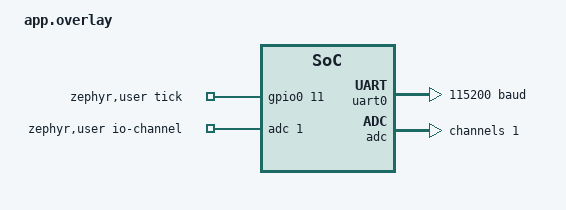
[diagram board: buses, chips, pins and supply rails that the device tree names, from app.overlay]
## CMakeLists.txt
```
# SPDX-License-Identifier: Apache-2.0

cmake_minimum_required(VERSION 3.20.0)
find_package(Zephyr REQUIRED HINTS $ENV{ZEPHYR_BASE})
project(nohrd_bike)

target_sources(app PRIVATE src/main.c src/ble_ftms.c src/ble_hr.c)
```

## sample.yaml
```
sample:
  name: NOHRD Bike Controller
tests:
  app.nohrd_bike:
    tags:
      - bike
      - display
      - bluetooth
      - gpio
    depends_on:
      - gpio
      - adc
      - bluetooth
    harness: led
    integration_platforms:
      - nrf52dk_nrf52832
```

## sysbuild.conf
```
SB_CONFIG_BOOTLOADER_MCUBOOT=y
SB_CONFIG_BOOT_SIGNATURE_TYPE_ECDSA_P256=y
SB_CONFIG_BOOT_SIGNATURE_KEY_FILE="${APPLICATION_CONFIG_DIR}/keys/nohrd-bike-mcuboot-ec256.pem"
SB_CONFIG_PM_EXTERNAL_FLASH_MCUBOOT_SECONDARY=y
```

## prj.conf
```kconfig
CONFIG_GPIO=y
CONFIG_ADC=y
CONFIG_FLASH=y
CONFIG_FLASH_MAP=y
CONFIG_FLASH_PAGE_LAYOUT=y
CONFIG_NVS=y
CONFIG_SPI=y
CONFIG_SPI_NOR=y
CONFIG_SPI_NOR_SFDP_MINIMAL=y
CONFIG_SPI_NOR_FLASH_LAYOUT_PAGE_SIZE=4096
CONFIG_SERIAL=y
CONFIG_UART_INTERRUPT_DRIVEN=y
CONFIG_CONSOLE=n
CONFIG_UART_CONSOLE=n
CONFIG_BT=y
CONFIG_BT_PERIPHERAL=y
CONFIG_BT_CENTRAL=y
CONFIG_BT_GATT_CLIENT=y
CONFIG_BT_GATT_DYNAMIC_DB=y
CONFIG_BT_MAX_CONN=2
CONFIG_BT_DEVICE_NAME="NOHRDNB"
CONFIG_BT_DEVICE_APPEARANCE=1152
CONFIG_BT_DIS=y
CONFIG_BT_DIS_MANUF_NAME=y
CONFIG_BT_DIS_MANUF_NAME_STR="waterrower nohrd"
CONFIG_BT_DIS_HW_REV=y
CONFIG_BT_DIS_HW_REV_STR="4.0"
CONFIG_BT_DIS_FW_REV=y
CONFIG_BT_DIS_FW_REV_STR="4.0"
CONFIG_BT_DIS_SW_REV=y
CONFIG_BT_DIS_SW_REV_STR="4.9"
```

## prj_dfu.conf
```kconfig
CONFIG_STREAM_FLASH=y
CONFIG_IMG_MANAGER=y
CONFIG_IMG_ERASE_PROGRESSIVELY=y
CONFIG_BOOTLOADER_MCUBOOT=y
CONFIG_MCUBOOT_BOOTUTIL_LIB=y
CONFIG_SPI=y
CONFIG_SPI_NOR=y
CONFIG_SPI_NOR_SFDP_MINIMAL=y
CONFIG_SPI_NOR_FLASH_LAYOUT_PAGE_SIZE=4096

CONFIG_NET_BUF=y
CONFIG_ZCBOR=y
CONFIG_CRC=y
CONFIG_MCUMGR=y
CONFIG_MCUMGR_GRP_IMG=y
CONFIG_MCUMGR_GRP_OS=y
CONFIG_MCUMGR_TRANSPORT_BT=y
CONFIG_MCUMGR_TRANSPORT_BT_PERM_RW=y
CONFIG_MCUMGR_TRANSPORT_BT_CONN_PARAM_CONTROL=y
CONFIG_MCUMGR_TRANSPORT_BT_REASSEMBLY=y
CONFIG_MCUMGR_TRANSPORT_NETBUF_SIZE=1220
CONFIG_MCUMGR_GRP_OS_MCUMGR_PARAMS=y
CONFIG_MCUMGR_TRANSPORT_WORKQUEUE_STACK_SIZE=4608
CONFIG_MCUMGR_TRANSPORT_UART=n

CONFIG_BT_L2CAP_TX_MTU=247
CONFIG_BT_BUF_ACL_RX_SIZE=251
CONFIG_BT_BUF_ACL_TX_SIZE=251
CONFIG_BT_CTLR_DATA_LENGTH_MAX=251
CONFIG_BT_ASSERT=n
CONFIG_BT_DIS_MODEL_NUMBER=n
CONFIG_BT_DIS_PNP=n
CONFIG_SYSTEM_WORKQUEUE_STACK_SIZE=2304
CONFIG_MAIN_STACK_SIZE=3072

CONFIG_MINIMAL_LIBC=y
```

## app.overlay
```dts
&pinctrl {
	uart0_default: uart0_default {
		group1 {
			psels = <NRF_PSEL(UART_TX, 0, 6)>,
				<NRF_PSEL(UART_RX, 0, 8)>;
		};
	};

	uart0_sleep: uart0_sleep {
		group1 {
			psels = <NRF_PSEL(UART_RX, 0, 8)>;
			low-power-enable;
		};

		group2 {
			psels = <NRF_PSEL(UART_TX, 0, 6)>;
			low-power-enable;
			bias-pull-up;
		};
	};
};

&uart0 {
	status = "okay";
	current-speed = <115200>;
	/delete-property/ hw-flow-control;
};

/ {
	zephyr,user {
		io-channels = <&adc 1>;
		tick-gpios = <&gpio0 11 GPIO_ACTIVE_HIGH>;
	};
};

&adc {
	#address-cells = <1>;
	#size-cells = <0>;
	status = "okay";

	channel@1 {
		reg = <1>;
		zephyr,gain = "ADC_GAIN_1_6";
		zephyr,reference = "ADC_REF_INTERNAL";
		zephyr,acquisition-time = <ADC_ACQ_TIME_DEFAULT>;
		zephyr,input-positive = <NRF_SAADC_AIN1>;
		zephyr,resolution = <12>;
	};
};
```

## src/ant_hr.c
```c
#include "ant_hr.h"

#include <errno.h>

static enum ant_hr_state ant_state = ANT_HR_UNAVAILABLE;

int ant_hr_init(void)
{
	return -ENOTSUP;
}

int ant_hr_start_pairing(void)
{
	ant_state = ANT_HR_UNAVAILABLE;
	return -ENOTSUP;
}

int ant_hr_disconnect(void)
{
	ant_state = ANT_HR_UNAVAILABLE;
	return 0;
}

void ant_hr_process(void)
{
}

enum ant_hr_state ant_hr_get_state(void)
{
	return ant_state;
}

bool ant_hr_is_connected(void)
{
	return ant_state == ANT_HR_CONNECTED;
}

uint8_t ant_hr_get_bpm(void)
{
	return 0U;
}

const char *ant_hr_get_name(void)
{
	return "ANT+";
}
```

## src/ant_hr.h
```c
#ifndef ANT_HR_H
#define ANT_HR_H

#include <stdbool.h>
#include <stdint.h>

enum ant_hr_state {
	ANT_HR_IDLE,
	ANT_HR_SEARCHING,
	ANT_HR_CONNECTED,
	ANT_HR_FAILED,
	ANT_HR_UNAVAILABLE,
};

int ant_hr_init(void);
int ant_hr_start_pairing(void);
int ant_hr_disconnect(void);
void ant_hr_process(void);
enum ant_hr_state ant_hr_get_state(void);
bool ant_hr_is_connected(void);
uint8_t ant_hr_get_bpm(void);
const char *ant_hr_get_name(void);

#endif
```

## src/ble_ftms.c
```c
#include "ble_ftms.h"

#include <errno.h>
#include <stddef.h>
#include <string.h>
#include <zephyr/bluetooth/bluetooth.h>
#include <zephyr/bluetooth/conn.h>
#include <zephyr/bluetooth/gatt.h>
#include <zephyr/bluetooth/uuid.h>
#ifdef CONFIG_MCUMGR_TRANSPORT_BT
#include <zephyr/mgmt/mcumgr/transport/smp_bt.h>
#endif
#include <zephyr/sys/byteorder.h>

#define BT_UUID_FTMS_VAL 0x1826
#define BT_UUID_FTMS_FEATURE_VAL 0x2acc
#define BT_UUID_INDOOR_BIKE_DATA_VAL 0x2ad2
#define BT_UUID_SUPPORTED_INCLINATION_RANGE_VAL 0x2ad5
#define BT_UUID_SUPPORTED_RESISTANCE_RANGE_VAL 0x2ad6
#define BT_UUID_SUPPORTED_HEART_RATE_RANGE_VAL 0x2ad7
#define BT_UUID_SUPPORTED_POWER_RANGE_VAL 0x2ad8
#define BT_UUID_FITNESS_MACHINE_STATUS_VAL 0x2ada

#define FTMS_STATUS_STOPPED_OR_PAUSED_BY_USER 0x02
#define FTMS_STATUS_STARTED_OR_RESUMED_BY_USER 0x04

static struct bt_conn *current_conn;
static bool bt_ready;
static bool ftms_enabled;
static bool ftms_advertising;
static bool heart_rate_notify_enabled;
static bool indoor_bike_notify_enabled;
static bool ftms_status_notify_enabled;
static bool custom_nohrd_indicate_enabled;
static bool custom_nohrd_notify_enabled;
static int ftms_last_error;
static bool custom_nohrd_indication_pending;
static const uint8_t *custom_nohrd_queued_data;
static size_t custom_nohrd_queued_len;
static struct bt_gatt_indicate_params custom_nohrd_indicate_params;
static ble_ftms_calibration_status_cb_t calibration_status_cb;
static ble_ftms_calibration_set_cb_t calibration_set_cb;

static const struct bt_uuid_16 heart_rate_service_uuid = BT_UUID_INIT_16(BT_UUID_HRS_VAL);
static const struct bt_uuid_16 heart_rate_measurement_uuid =
	BT_UUID_INIT_16(BT_UUID_HRS_MEASUREMENT_VAL);
static const struct bt_uuid_16 ftms_uuid = BT_UUID_INIT_16(BT_UUID_FTMS_VAL);
static const struct bt_uuid_16 ftms_feature_uuid =
	BT_UUID_INIT_16(BT_UUID_FTMS_FEATURE_VAL);
static const struct bt_uuid_16 supported_inclination_range_uuid =
	BT_UUID_INIT_16(BT_UUID_SUPPORTED_INCLINATION_RANGE_VAL);
static const struct bt_uuid_16 supported_resistance_range_uuid =
	BT_UUID_INIT_16(BT_UUID_SUPPORTED_RESISTANCE_RANGE_VAL);
static const struct bt_uuid_16 supported_heart_rate_range_uuid =
	BT_UUID_INIT_16(BT_UUID_SUPPORTED_HEART_RATE_RANGE_VAL);
static const struct bt_uuid_16 supported_power_range_uuid =
	BT_UUID_INIT_16(BT_UUID_SUPPORTED_POWER_RANGE_VAL);
static const struct bt_uuid_16 indoor_bike_data_uuid =
	BT_UUID_INIT_16(BT_UUID_INDOOR_BIKE_DATA_VAL);
static const struct bt_uuid_16 fitness_machine_status_uuid =
	BT_UUID_INIT_16(BT_UUID_FITNESS_MACHINE_STATUS_VAL);
static const struct bt_uuid_128 custom_nohrd_bike_service_uuid =
	BT_UUID_INIT_128(BT_UUID_128_ENCODE(0x00001001, 0xc042, 0x66ba,
					    0x1335, 0x90118f542c77));
static const struct bt_uuid_128 custom_nohrd_bike_write_uuid =
	BT_UUID_INIT_128(BT_UUID_128_ENCODE(0x8ec92001, 0xf315, 0x4f60,
					    0x9fb8, 0x838830daea50));
static const struct bt_uuid_128 custom_nohrd_bike_notify_uuid =
	BT_UUID_INIT_128(BT_UUID_128_ENCODE(0x8ec92002, 0xf315, 0x4f60,
					    0x9fb8, 0x838830daea50));

extern const struct bt_gatt_service_static ftms_service;
extern const struct bt_gatt_service_static custom_nohrd_bike_service;

static const uint8_t ftms_feature[8] = {
	0x04, 0x04, 0x00, 0x00,
	0x00, 0x00, 0x00, 0x00,
};
static const uint8_t supported_inclination_range[6] = {
	0x18, 0xfc, 0xe8, 0x03, 0x01, 0x00,
};
static const uint8_t supported_resistance_range[6] = {
	0x00, 0x00, 0xe8, 0x03, 0x01, 0x00,
};
static const uint8_t supported_heart_rate_range[3] = {
	0x00, 0xff, 0x01,
};
static const uint8_t supported_power_range[6] = {
	0x00, 0x00, 0xa0, 0x0f, 0x01, 0x00,
};

static const struct bt_data advertising_data[] = {
	BT_DATA_BYTES(BT_DATA_FLAGS, (BT_LE_AD_GENERAL | BT_LE_AD_NO_BREDR)),
	BT_DATA_BYTES(BT_DATA_UUID16_ALL,
		      BT_UUID_16_ENCODE(BT_UUID_FTMS_VAL),
		      BT_UUID_16_ENCODE(BT_UUID_DIS_VAL)),
	BT_DATA_BYTES(BT_DATA_SVC_DATA16, BT_UUID_16_ENCODE(BT_UUID_FTMS_VAL),
		      0x01, 0x20, 0x00),
	BT_DATA(BT_DATA_NAME_COMPLETE, CONFIG_BT_DEVICE_NAME,
		sizeof(CONFIG_BT_DEVICE_NAME) - 1),
};

#ifdef CONFIG_MCUMGR_TRANSPORT_BT
static const struct bt_data scan_response_data[] = {
	BT_DATA_BYTES(BT_DATA_UUID128_ALL, SMP_BT_SVC_UUID_VAL),
};
#endif

static ssize_t read_ftms_feature(struct bt_conn *conn,
				 const struct bt_gatt_attr *attr,
				 void *buf, uint16_t len, uint16_t offset)
{
	return bt_gatt_attr_read(conn, attr, buf, len, offset,
				 ftms_feature, sizeof(ftms_feature));
}

static ssize_t read_supported_inclination_range(struct bt_conn *conn,
						const struct bt_gatt_attr *attr,
						void *buf, uint16_t len,
						uint16_t offset)
{
	return bt_gatt_attr_read(conn, attr, buf, len, offset,
				 supported_inclination_range,
				 sizeof(supported_inclination_range));
}

static ssize_t read_supported_resistance_range(struct bt_conn *conn,
					       const struct bt_gatt_attr *attr,
					       void *buf, uint16_t len,
					       uint16_t offset)
{
	return bt_gatt_attr_read(conn, attr, buf, len, offset,
				 supported_resistance_range,
				 sizeof(supported_resistance_range));
}

static ssize_t read_supported_heart_rate_range(struct bt_conn *conn,
					       const struct bt_gatt_attr *attr,
					       void *buf, uint16_t len,
					       uint16_t offset)
{
	return bt_gatt_attr_read(conn, attr, buf, len, offset,
				 supported_heart_rate_range,
				 sizeof(supported_heart_rate_range));
}

static ssize_t read_supported_power_range(struct bt_conn *conn,
					  const struct bt_gatt_attr *attr,
					  void *buf, uint16_t len,
					  uint16_t offset)
{
	return bt_gatt_attr_read(conn, attr, buf, len, offset,
				 supported_power_range,
				 sizeof(supported_power_range));
}

static void heart_rate_ccc_changed(const struct bt_gatt_attr *attr,
				   uint16_t value)
{
	ARG_UNUSED(attr);

	heart_rate_notify_enabled = (value == BT_GATT_CCC_NOTIFY);
}

static void indoor_bike_ccc_changed(const struct bt_gatt_attr *attr,
				    uint16_t value)
{
	ARG_UNUSED(attr);

	indoor_bike_notify_enabled = (value == BT_GATT_CCC_NOTIFY);
}

static void fitness_machine_status_ccc_changed(const struct bt_gatt_attr *attr,
					       uint16_t value)
{
	ARG_UNUSED(attr);

	ftms_status_notify_enabled = (value == BT_GATT_CCC_NOTIFY);
}

static void custom_nohrd_ccc_changed(const struct bt_gatt_attr *attr,
				     uint16_t value)
{
	ARG_UNUSED(attr);

	custom_nohrd_indicate_enabled = (value == BT_GATT_CCC_INDICATE);
}

static void custom_nohrd_notify_ccc_changed(const struct bt_gatt_attr *attr,
					    uint16_t value)
{
	ARG_UNUSED(attr);

	custom_nohrd_notify_enabled = (value == BT_GATT_CCC_NOTIFY);
}

static int custom_nohrd_start_indication(const uint8_t *data, size_t len);

static void custom_nohrd_indicate_cb(struct bt_conn *conn,
				     struct bt_gatt_indicate_params *params,
				     uint8_t err)
{
	const uint8_t *queued_data;
	size_t queued_len;

	ARG_UNUSED(conn);
	ARG_UNUSED(params);
	ARG_UNUSED(err);

	custom_nohrd_indication_pending = false;

	if (custom_nohrd_queued_data != NULL) {
		queued_data = custom_nohrd_queued_data;
		queued_len = custom_nohrd_queued_len;
		custom_nohrd_queued_data = NULL;
		custom_nohrd_queued_len = 0U;
		(void)custom_nohrd_start_indication(queued_data, queued_len);
	}
}

static int custom_nohrd_start_indication(const uint8_t *data, size_t len)
{
	int err;

	if (current_conn == NULL || !custom_nohrd_indicate_enabled) {
		return 0;
	}

	memset(&custom_nohrd_indicate_params, 0,
	       sizeof(custom_nohrd_indicate_params));
	custom_nohrd_indicate_params.attr = &custom_nohrd_bike_service.attrs[2];
	custom_nohrd_indicate_params.data = data;
	custom_nohrd_indicate_params.len = len;
	custom_nohrd_indicate_params.func = custom_nohrd_indicate_cb;
	custom_nohrd_indication_pending = true;

	err = bt_gatt_indicate(current_conn, &custom_nohrd_indicate_params);
	if (err != 0) {
		custom_nohrd_indication_pending = false;
	}

	return err;
}

static int custom_nohrd_send(const uint8_t *data, size_t len)
{
	if (current_conn == NULL) {
		return 0;
	}

	if (custom_nohrd_notify_enabled) {
		return bt_gatt_notify_uuid(current_conn,
					   &custom_nohrd_bike_notify_uuid.uuid,
					   custom_nohrd_bike_service.attrs,
					   data, len);
	}

	if (!custom_nohrd_indicate_enabled || custom_nohrd_indication_pending) {
		if (custom_nohrd_indicate_enabled &&
		    custom_nohrd_queued_data == NULL) {
			custom_nohrd_queued_data = data;
			custom_nohrd_queued_len = len;
		}
		return 0;
	}

	return custom_nohrd_start_indication(data, len);
}

static void custom_nohrd_send_response(bool success)
{
	static const uint8_t response_success[] = {
		0xe2, 0xb0, 0xfe, 0x01, 0x01, 0x01, 0x00, 0x00,
	};
	static const uint8_t response_fail[] = {
		0xe2, 0xb0, 0xfe, 0x01, 0x02, 0x01, 0x00, 0x00,
	};

	(void)custom_nohrd_send(success ? response_success : response_fail,
				success ? sizeof(response_success) :
					  sizeof(response_fail));
}

static void custom_nohrd_send_calibrated(bool calibrated)
{
	static const uint8_t calibrated_ack[] = {
		0xe2, 0xb0, 0xfe, 0x40, 0x01, 0x00, 0x00, 0x00,
	};
	static const uint8_t calibrated_nack[] = {
		0xe2, 0xb0, 0xfe, 0x40, 0x02, 0x00, 0x00, 0x00,
	};

	(void)custom_nohrd_send(calibrated ? calibrated_ack : calibrated_nack,
				calibrated ? sizeof(calibrated_ack) :
					     sizeof(calibrated_nack));
}

static void custom_nohrd_send_transition(uint8_t transition)
{
	static const uint8_t ready[] = {0xe2, 0xd2, 0x00};
	static const uint8_t in_use[] = {0xe2, 0xd2, 0x01};
	static const uint8_t finished[] = {0xe2, 0xd2, 0x02};
	const uint8_t *data = ready;

	if (transition == 0x01) {
		data = in_use;
	} else if (transition == 0x02) {
		data = finished;
	}

	(void)custom_nohrd_send(data, sizeof(ready));
}

static int ftms_notify_status(uint8_t status, uint8_t parameter)
{
	uint8_t data[] = {status, parameter};

	if (current_conn == NULL || !ftms_status_notify_enabled) {
		return 0;
	}

	return bt_gatt_notify_uuid(current_conn,
				   &fitness_machine_status_uuid.uuid,
				   ftms_service.attrs, data, sizeof(data));
}

static int custom_nohrd_protocol_offset(const uint8_t *data, size_t len)
{
	for (size_t i = 0; i < len; i++) {
		if (data[i] == 0xfe) {
			return (int)i;
		}
	}

	return -1;
}

static ssize_t write_custom_nohrd(struct bt_conn *conn,
				  const struct bt_gatt_attr *attr,
				  const void *buf, uint16_t len,
				  uint16_t offset, uint8_t flags)
{
	const uint8_t *data = buf;
	bool success = false;
	int protocol_offset;
	size_t cmd_offset;

	ARG_UNUSED(conn);
	ARG_UNUSED(attr);
	ARG_UNUSED(flags);

	if (offset != 0U) {
		return BT_GATT_ERR(BT_ATT_ERR_INVALID_OFFSET);
	}

	protocol_offset = custom_nohrd_protocol_offset(data, len);
	if (protocol_offset < 0 || (size_t)protocol_offset + 2U >= len) {
		custom_nohrd_send_response(false);
		return len;
	}

	cmd_offset = (size_t)protocol_offset + 1U;

	switch (data[cmd_offset]) {
	case 0x01:
		if (cmd_offset + 1U < len && calibration_set_cb != NULL) {
			success = calibration_set_cb(data[cmd_offset + 1U],
						    &data[cmd_offset + 2U],
						    len - (cmd_offset + 2U)) == 0;
		}
		custom_nohrd_send_response(success);
		break;
	case 0x02:
		success = cmd_offset + 1U < len &&
			  (data[cmd_offset + 1U] == 0x01 ||
			   data[cmd_offset + 1U] == 0x02);
		custom_nohrd_send_response(success);
		break;
	case 0x04:
		custom_nohrd_send_response(true);
		custom_nohrd_send_calibrated(calibration_status_cb != NULL &&
					     calibration_status_cb());
		break;
	default:
		custom_nohrd_send_response(false);
		break;
	}

	return len;
}

/* Registered dynamically (see ble_ftms_hrs_set_active) only once a BLE HR
 * sensor is actually connected, so idle FTMS-only clients never see an
 * advertised Heart Rate Service that has no data behind it. */
static const struct bt_gatt_attr heart_rate_attrs[] = {
	BT_GATT_PRIMARY_SERVICE(&heart_rate_service_uuid.uuid),
	BT_GATT_CHARACTERISTIC(&heart_rate_measurement_uuid.uuid,
			       BT_GATT_CHRC_NOTIFY,
			       BT_GATT_PERM_NONE,
			       NULL, NULL, NULL),
	BT_GATT_CCC(heart_rate_ccc_changed,
		    BT_GATT_PERM_READ | BT_GATT_PERM_WRITE),
};

static struct bt_gatt_service heart_rate_service = BT_GATT_SERVICE(heart_rate_attrs);
static bool heart_rate_service_registered;

BT_GATT_SERVICE_DEFINE(ftms_service,
	BT_GATT_PRIMARY_SERVICE(&ftms_uuid.uuid),
	BT_GATT_CHARACTERISTIC(&ftms_feature_uuid.uuid,
			       BT_GATT_CHRC_READ,
			       BT_GATT_PERM_READ,
			       read_ftms_feature, NULL, NULL),
	BT_GATT_CHARACTERISTIC(&supported_inclination_range_uuid.uuid,
			       BT_GATT_CHRC_READ,
			       BT_GATT_PERM_READ,
			       read_supported_inclination_range, NULL, NULL),
	BT_GATT_CHARACTERISTIC(&supported_resistance_range_uuid.uuid,
			       BT_GATT_CHRC_READ,
			       BT_GATT_PERM_READ,
			       read_supported_resistance_range, NULL, NULL),
	BT_GATT_CHARACTERISTIC(&supported_heart_rate_range_uuid.uuid,
			       BT_GATT_CHRC_READ,
			       BT_GATT_PERM_READ,
			       read_supported_heart_rate_range, NULL, NULL),
	BT_GATT_CHARACTERISTIC(&supported_power_range_uuid.uuid,
			       BT_GATT_CHRC_READ,
			       BT_GATT_PERM_READ,
			       read_supported_power_range, NULL, NULL),
	BT_GATT_CHARACTERISTIC(&indoor_bike_data_uuid.uuid,
			       BT_GATT_CHRC_NOTIFY,
			       BT_GATT_PERM_NONE,
			       NULL, NULL, NULL),
	BT_GATT_CCC(indoor_bike_ccc_changed,
		    BT_GATT_PERM_READ | BT_GATT_PERM_WRITE),
	BT_GATT_CHARACTERISTIC(&fitness_machine_status_uuid.uuid,
			       BT_GATT_CHRC_NOTIFY,
			       BT_GATT_PERM_NONE,
			       NULL, NULL, NULL),
	BT_GATT_CCC(fitness_machine_status_ccc_changed,
		    BT_GATT_PERM_READ | BT_GATT_PERM_WRITE),
);

BT_GATT_SERVICE_DEFINE(custom_nohrd_bike_service,
	BT_GATT_PRIMARY_SERVICE(&custom_nohrd_bike_service_uuid.uuid),
	BT_GATT_CHARACTERISTIC(&custom_nohrd_bike_write_uuid.uuid,
			       BT_GATT_CHRC_WRITE |
			       BT_GATT_CHRC_INDICATE,
			       BT_GATT_PERM_WRITE,
			       NULL, write_custom_nohrd, NULL),
	BT_GATT_CCC(custom_nohrd_ccc_changed,
		    BT_GATT_PERM_READ | BT_GATT_PERM_WRITE),
	BT_GATT_CHARACTERISTIC(&custom_nohrd_bike_notify_uuid.uuid,
			       BT_GATT_CHRC_NOTIFY,
			       BT_GATT_PERM_NONE,
			       NULL, NULL, NULL),
	BT_GATT_CCC(custom_nohrd_notify_ccc_changed,
		    BT_GATT_PERM_READ | BT_GATT_PERM_WRITE),
);

static int start_advertising(void)
{
	int err;

	if (!bt_ready || ftms_advertising || current_conn != NULL) {
		return 0;
	}

	err = bt_le_adv_start(BT_LE_ADV_CONN_FAST_2,
			      advertising_data, ARRAY_SIZE(advertising_data),
#ifdef CONFIG_MCUMGR_TRANSPORT_BT
			      scan_response_data, ARRAY_SIZE(scan_response_data));
#else
			      NULL, 0);
#endif
	if (err == -EALREADY) {
		err = 0;
	}

	if (err == 0) {
		ftms_advertising = true;
	}

	return err;
}

static int stop_advertising(void)
{
	int err;

	if (!ftms_advertising) {
		return 0;
	}

	err = bt_le_adv_stop();
	if (err == -EALREADY || err == -EINVAL || err == -EACCES) {
		err = 0;
	}

	if (err == 0) {
		ftms_advertising = false;
	}

	return err;
}

int ble_ftms_hrs_set_active(bool active)
{
	int err;

	if (active == heart_rate_service_registered) {
		return 0;
	}

	if (active) {
		err = bt_gatt_service_register(&heart_rate_service);
	} else {
		heart_rate_notify_enabled = false;
		err = bt_gatt_service_unregister(&heart_rate_service);
	}

	if (err == 0) {
		heart_rate_service_registered = active;
	}

	return err;
}

int ble_ftms_notify_heart_rate(uint8_t bpm)
{
	uint8_t data[2] = { 0x00, bpm };

	if (current_conn == NULL || !heart_rate_service_registered ||
	    !heart_rate_notify_enabled) {
		return 0;
	}

	return bt_gatt_notify_uuid(current_conn, &heart_rate_measurement_uuid.uuid,
				   heart_rate_attrs, data, sizeof(data));
}

int ble_ftms_pause_advertising(void)
{
	return stop_advertising();
}

int ble_ftms_resume_advertising(void)
{
	if (!ftms_enabled) {
		return 0;
	}

	return start_advertising();
}

static void connected(struct bt_conn *conn, uint8_t err)
{
	struct bt_conn_info info;

	if (bt_conn_get_info(conn, &info) != 0) {
		return;
	}

	if (info.role != BT_CONN_ROLE_PERIPHERAL) {
		return;
	}

	if (err != 0) {
		if (ftms_enabled) {
			(void)start_advertising();
		}
		return;
	}

	current_conn = bt_conn_ref(conn);
	ftms_advertising = false;
}

static void disconnected(struct bt_conn *conn, uint8_t reason)
{
	ARG_UNUSED(reason);

	if (current_conn != conn) {
		return;
	}

	bt_conn_unref(current_conn);
	current_conn = NULL;
	heart_rate_notify_enabled = false;
	indoor_bike_notify_enabled = false;
	ftms_status_notify_enabled = false;
	custom_nohrd_indicate_enabled = false;
	custom_nohrd_notify_enabled = false;
	custom_nohrd_indication_pending = false;
	custom_nohrd_queued_data = NULL;
	custom_nohrd_queued_len = 0U;

	if (ftms_enabled) {
		(void)start_advertising();
	}
}

BT_CONN_CB_DEFINE(conn_callbacks) = {
	.connected = connected,
	.disconnected = disconnected,
};

int ble_ftms_init(void)
{
	int err;

	if (bt_ready) {
		return 0;
	}

	err = bt_enable(NULL);
	if (err == 0) {
		bt_ready = true;
	}
	ftms_last_error = err;

	return err;
}

int ble_ftms_set_enabled(bool enabled)
{
	int err;

	if (!bt_ready) {
		err = ble_ftms_init();
		if (err != 0) {
			ftms_last_error = err;
			return err;
		}
	}

	if (enabled) {
		err = start_advertising();
		ftms_last_error = err;
		if (err == 0) {
			ftms_enabled = true;
		}
		return err;
	}

	ftms_enabled = false;
	err = stop_advertising();

	if (current_conn != NULL) {
		int disconnect_err = bt_conn_disconnect(current_conn,
							BT_HCI_ERR_REMOTE_USER_TERM_CONN);
		if (err == 0) {
			err = disconnect_err;
		}
	}

	ftms_last_error = err;
	return err;
}

int ble_ftms_last_error(void)
{
	return ftms_last_error;
}

bool ble_ftms_is_enabled(void)
{
	return ftms_enabled;
}

bool ble_ftms_is_connected(void)
{
	return current_conn != NULL;
}

int ble_ftms_disconnect(void)
{
	if (current_conn == NULL) {
		return 0;
	}

	return bt_conn_disconnect(current_conn, BT_HCI_ERR_REMOTE_USER_TERM_CONN);
}

void ble_ftms_set_calibration_handlers(ble_ftms_calibration_status_cb_t status_cb,
				       ble_ftms_calibration_set_cb_t set_cb)
{
	calibration_status_cb = status_cb;
	calibration_set_cb = set_cb;
}

int ble_ftms_notify_session_started(void)
{
	custom_nohrd_send_transition(0x01);

	return ftms_notify_status(FTMS_STATUS_STARTED_OR_RESUMED_BY_USER, 0x00);
}

int ble_ftms_notify_session_ended(void)
{
	int err;

	custom_nohrd_send_transition(0x02);
	custom_nohrd_send_transition(0x00);

	err = ftms_notify_status(FTMS_STATUS_STOPPED_OR_PAUSED_BY_USER, 0x01);
	if (err == -ENOTCONN) {
		err = 0;
	}

	return err;
}

int ble_ftms_notify_indoor_bike(uint16_t speed_centi_kmh, uint16_t cadence_half_rpm,
				int16_t resistance_percent, int16_t power_watt)
{
	uint8_t data[10];

	if (current_conn == NULL || !indoor_bike_notify_enabled) {
		return 0;
	}

	sys_put_le16(0x0064, &data[0]);
	sys_put_le16(speed_centi_kmh, &data[2]);
	sys_put_le16(cadence_half_rpm, &data[4]);
	sys_put_le16((uint16_t)(resistance_percent * 2), &data[6]);
	sys_put_le16((uint16_t)power_watt, &data[8]);

	return bt_gatt_notify_uuid(current_conn, &indoor_bike_data_uuid.uuid,
				   ftms_service.attrs, data, sizeof(data));
}
```

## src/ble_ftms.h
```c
#ifndef BLE_FTMS_H
#define BLE_FTMS_H

#include <stdbool.h>
#include <stddef.h>
#include <stdint.h>

typedef bool (*ble_ftms_calibration_status_cb_t)(void);
typedef int (*ble_ftms_calibration_set_cb_t)(uint8_t value_id,
					     const uint8_t *data,
					     size_t len);

int ble_ftms_init(void);
int ble_ftms_set_enabled(bool enabled);
int ble_ftms_last_error(void);
bool ble_ftms_is_enabled(void);
bool ble_ftms_is_connected(void);
int ble_ftms_disconnect(void);
void ble_ftms_set_calibration_handlers(ble_ftms_calibration_status_cb_t status_cb,
				       ble_ftms_calibration_set_cb_t set_cb);
int ble_ftms_pause_advertising(void);
int ble_ftms_resume_advertising(void);
int ble_ftms_hrs_set_active(bool active);
int ble_ftms_notify_heart_rate(uint8_t bpm);
int ble_ftms_notify_session_started(void);
int ble_ftms_notify_session_ended(void);
int ble_ftms_notify_indoor_bike(uint16_t speed_centi_kmh, uint16_t cadence_half_rpm,
				int16_t resistance_percent, int16_t power_watt);

#endif
```

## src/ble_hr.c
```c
#include "ble_hr.h"

#ifdef CONFIG_BT_CENTRAL

#include <errno.h>
#include <stddef.h>
#include <string.h>
#include <zephyr/bluetooth/bluetooth.h>
#include <zephyr/bluetooth/conn.h>
#include <zephyr/bluetooth/gatt.h>
#include <zephyr/bluetooth/hci.h>
#include <zephyr/bluetooth/uuid.h>
#include <zephyr/kernel.h>
#include <zephyr/sys/byteorder.h>

#include "ble_ftms.h"

#define HR_SCAN_MS 5000U
#define HR_NAME_MAX 10U

struct hr_candidate {
	bt_addr_le_t addr;
	int8_t rssi;
	char name[HR_NAME_MAX + 1U];
	bool found;
};

struct adv_parse_context {
	bool has_hrs;
	char name[HR_NAME_MAX + 1U];
};

static struct bt_conn *hr_conn;
static struct bt_uuid_16 discover_uuid = BT_UUID_INIT_16(0);
static struct bt_gatt_discover_params discover_params;
static struct bt_gatt_subscribe_params subscribe_params;
static struct hr_candidate best_candidate;
static enum ble_hr_state hr_state = BLE_HR_IDLE;
static uint32_t scan_started_ms;
static uint8_t hr_bpm;
static char hr_name[HR_NAME_MAX + 1U] = "Sensor";
static int8_t hr_rssi;

static void copy_bounded(char *dst, size_t dst_size, const char *src)
{
	size_t len = strlen(src);

	if (len >= dst_size) {
		len = dst_size - 1U;
	}
	memcpy(dst, src, len);
	dst[len] = '\0';
}

static bool adv_parse(struct bt_data *data, void *user_data)
{
	struct adv_parse_context *context = user_data;

	switch (data->type) {
	case BT_DATA_UUID16_SOME:
	case BT_DATA_UUID16_ALL:
		for (uint8_t i = 0; i + sizeof(uint16_t) <= data->data_len;
		     i += sizeof(uint16_t)) {
			uint16_t uuid = sys_get_le16(&data->data[i]);

			if (uuid == BT_UUID_HRS_VAL) {
				context->has_hrs = true;
			}
		}
		break;
	case BT_DATA_NAME_SHORTENED:
	case BT_DATA_NAME_COMPLETE:
		memcpy(context->name, data->data,
		       MIN(data->data_len, HR_NAME_MAX));
		context->name[MIN(data->data_len, HR_NAME_MAX)] = '\0';
		break;
	default:
		break;
	}

	return true;
}

static void device_found(const bt_addr_le_t *addr, int8_t rssi, uint8_t type,
			 struct net_buf_simple *ad)
{
	struct adv_parse_context context = {0};

	if (hr_state != BLE_HR_SCANNING) {
		return;
	}

	if (type != BT_GAP_ADV_TYPE_ADV_IND &&
	    type != BT_GAP_ADV_TYPE_ADV_DIRECT_IND &&
	    type != BT_GAP_ADV_TYPE_EXT_ADV) {
		return;
	}

	bt_data_parse(ad, adv_parse, &context);
	if (!context.has_hrs) {
		return;
	}

	if (!best_candidate.found || rssi > best_candidate.rssi) {
		bt_addr_le_copy(&best_candidate.addr, addr);
		best_candidate.rssi = rssi;
		best_candidate.found = true;
		if (context.name[0] != '\0') {
			memcpy(best_candidate.name, context.name,
			       sizeof(best_candidate.name));
		} else {
			copy_bounded(best_candidate.name,
				     sizeof(best_candidate.name), "HR Sensor");
		}
	}
}

static uint8_t notify_func(struct bt_conn *conn,
			   struct bt_gatt_subscribe_params *params,
			   const void *data, uint16_t length)
{
	const uint8_t *measurement = data;

	ARG_UNUSED(conn);

	if (data == NULL) {
		params->value_handle = 0U;
		hr_state = BLE_HR_IDLE;
		hr_bpm = 0U;
		(void)ble_ftms_hrs_set_active(false);
		return BT_GATT_ITER_STOP;
	}

	if (length < 2U) {
		return BT_GATT_ITER_CONTINUE;
	}

	if ((measurement[0] & 0x01U) != 0U) {
		if (length >= 3U) {
			uint16_t bpm16 = sys_get_le16(&measurement[1]);

			hr_bpm = bpm16 > 255U ? 255U : (uint8_t)bpm16;
		}
	} else {
		hr_bpm = measurement[1];
	}

	(void)ble_ftms_notify_heart_rate(hr_bpm);

	return BT_GATT_ITER_CONTINUE;
}

static uint8_t discover_func(struct bt_conn *conn,
			     const struct bt_gatt_attr *attr,
			     struct bt_gatt_discover_params *params)
{
	int err;

	if (attr == NULL) {
		memset(params, 0, sizeof(*params));
		if (hr_state == BLE_HR_CONNECTING) {
			hr_state = BLE_HR_FAILED;
		}
		return BT_GATT_ITER_STOP;
	}

	if (!bt_uuid_cmp(discover_params.uuid, BT_UUID_HRS)) {
		memcpy(&discover_uuid, BT_UUID_HRS_MEASUREMENT,
		       sizeof(discover_uuid));
		discover_params.uuid = &discover_uuid.uuid;
		discover_params.start_handle = attr->handle + 1U;
		discover_params.type = BT_GATT_DISCOVER_CHARACTERISTIC;

		err = bt_gatt_discover(conn, &discover_params);
		if (err != 0) {
			hr_state = BLE_HR_FAILED;
		}
		return BT_GATT_ITER_STOP;
	}

	if (!bt_uuid_cmp(discover_params.uuid, BT_UUID_HRS_MEASUREMENT)) {
		memcpy(&discover_uuid, BT_UUID_GATT_CCC, sizeof(discover_uuid));
		discover_params.uuid = &discover_uuid.uuid;
		discover_params.start_handle = attr->handle + 2U;
		discover_params.type = BT_GATT_DISCOVER_DESCRIPTOR;
		subscribe_params.value_handle = bt_gatt_attr_value_handle(attr);

		err = bt_gatt_discover(conn, &discover_params);
		if (err != 0) {
			hr_state = BLE_HR_FAILED;
		}
		return BT_GATT_ITER_STOP;
	}

	subscribe_params.notify = notify_func;
	subscribe_params.value = BT_GATT_CCC_NOTIFY;
	subscribe_params.ccc_handle = attr->handle;

	err = bt_gatt_subscribe(conn, &subscribe_params);
	if (err == 0 || err == -EALREADY) {
		hr_state = BLE_HR_CONNECTED;
		(void)ble_ftms_hrs_set_active(true);
	} else {
		hr_state = BLE_HR_FAILED;
	}

	return BT_GATT_ITER_STOP;
}

static void start_discovery(void)
{
	int err;

	if (hr_conn == NULL) {
		hr_state = BLE_HR_FAILED;
		return;
	}

	memcpy(&discover_uuid, BT_UUID_HRS, sizeof(discover_uuid));
	discover_params.uuid = &discover_uuid.uuid;
	discover_params.func = discover_func;
	discover_params.start_handle = BT_ATT_FIRST_ATTRIBUTE_HANDLE;
	discover_params.end_handle = BT_ATT_LAST_ATTRIBUTE_HANDLE;
	discover_params.type = BT_GATT_DISCOVER_PRIMARY;

	err = bt_gatt_discover(hr_conn, &discover_params);
	if (err != 0) {
		hr_state = BLE_HR_FAILED;
	}
}

static void connected(struct bt_conn *conn, uint8_t conn_err)
{
	struct bt_conn_info info;

	if (bt_conn_get_info(conn, &info) != 0 ||
	    info.role != BT_CONN_ROLE_CENTRAL) {
		return;
	}

	if (conn != hr_conn) {
		return;
	}

	if (conn_err != 0U) {
		bt_conn_unref(hr_conn);
		hr_conn = NULL;
		hr_state = BLE_HR_FAILED;
		return;
	}

	start_discovery();
}

static void disconnected(struct bt_conn *conn, uint8_t reason)
{
	ARG_UNUSED(reason);

	if (conn != hr_conn) {
		return;
	}

	bt_conn_unref(hr_conn);
	hr_conn = NULL;
	hr_bpm = 0U;
	if (hr_state == BLE_HR_CONNECTED || hr_state == BLE_HR_CONNECTING) {
		hr_state = BLE_HR_IDLE;
	}
	(void)ble_ftms_hrs_set_active(false);
}

BT_CONN_CB_DEFINE(hr_conn_callbacks) = {
	.connected = connected,
	.disconnected = disconnected,
};

int ble_hr_start_pairing(void)
{
	struct bt_le_scan_param scan_param = {
		.type = BT_LE_SCAN_TYPE_ACTIVE,
		.options = BT_LE_SCAN_OPT_NONE,
		.interval = BT_GAP_SCAN_FAST_INTERVAL,
		.window = BT_GAP_SCAN_FAST_WINDOW,
	};
	int err;

	err = ble_ftms_init();
	if (err != 0) {
		return err;
	}

	if (hr_conn != NULL) {
		(void)ble_hr_disconnect();
	}

	memset(&best_candidate, 0, sizeof(best_candidate));
	hr_bpm = 0U;
	hr_rssi = 0;
	copy_bounded(hr_name, sizeof(hr_name), "Suche");

	(void)ble_ftms_pause_advertising();

	err = bt_le_scan_start(&scan_param, device_found);
	if (err != 0) {
		hr_state = BLE_HR_FAILED;
		(void)ble_ftms_resume_advertising();
		return err;
	}

	scan_started_ms = k_uptime_get_32();
	hr_state = BLE_HR_SCANNING;
	return 0;
}

int ble_hr_disconnect(void)
{
	int err = 0;
	bool was_scanning = hr_state == BLE_HR_SCANNING;

	if (was_scanning) {
		err = bt_le_scan_stop();
		(void)ble_ftms_resume_advertising();
	}

	if (hr_conn != NULL) {
		int disconnect_err = bt_conn_disconnect(hr_conn,
							BT_HCI_ERR_REMOTE_USER_TERM_CONN);
		if (err == 0) {
			err = disconnect_err;
		}
	}

	hr_state = BLE_HR_IDLE;
	hr_bpm = 0U;
	return err;
}

void ble_hr_process(void)
{
	struct bt_conn_le_create_param *create_param;
	struct bt_le_conn_param *param;
	int err;

	if (hr_state != BLE_HR_SCANNING) {
		return;
	}

	if ((uint32_t)(k_uptime_get_32() - scan_started_ms) < HR_SCAN_MS) {
		return;
	}

	(void)bt_le_scan_stop();
	(void)ble_ftms_resume_advertising();

	if (!best_candidate.found) {
		hr_state = BLE_HR_FAILED;
		copy_bounded(hr_name, sizeof(hr_name), "Kein Gurt");
		return;
	}

	create_param = BT_CONN_LE_CREATE_CONN;
	param = BT_LE_CONN_PARAM_DEFAULT;
	err = bt_conn_le_create(&best_candidate.addr, create_param, param,
				&hr_conn);
	if (err != 0) {
		hr_state = BLE_HR_FAILED;
		copy_bounded(hr_name, sizeof(hr_name), "Fehler");
		return;
	}

	memcpy(hr_name, best_candidate.name, sizeof(hr_name));
	hr_rssi = best_candidate.rssi;
	hr_state = BLE_HR_CONNECTING;
}

enum ble_hr_state ble_hr_get_state(void)
{
	return hr_state;
}

bool ble_hr_is_connected(void)
{
	return hr_state == BLE_HR_CONNECTED;
}

uint8_t ble_hr_get_bpm(void)
{
	return hr_bpm;
}

int8_t ble_hr_get_rssi(void)
{
	return hr_rssi;
}

const char *ble_hr_get_name(void)
{
	return hr_name;
}

#else

#include <errno.h>
#include <stdbool.h>
#include <stdint.h>

int ble_hr_start_pairing(void)
{
	return -ENOTSUP;
}

int ble_hr_disconnect(void)
{
	return 0;
}

void ble_hr_process(void)
{
}

enum ble_hr_state ble_hr_get_state(void)
{
	return BLE_HR_IDLE;
}

bool ble_hr_is_connected(void)
{
	return false;
}

uint8_t ble_hr_get_bpm(void)
{
	return 0U;
}

int8_t ble_hr_get_rssi(void)
{
	return 0;
}

const char *ble_hr_get_name(void)
{
	return "Sensor";
}

#endif
```

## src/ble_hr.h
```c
#ifndef BLE_HR_H
#define BLE_HR_H

#include <stdbool.h>
#include <stdint.h>

enum ble_hr_state {
	BLE_HR_IDLE,
	BLE_HR_SCANNING,
	BLE_HR_CONNECTING,
	BLE_HR_CONNECTED,
	BLE_HR_FAILED,
};

int ble_hr_start_pairing(void);
int ble_hr_disconnect(void);
void ble_hr_process(void);
enum ble_hr_state ble_hr_get_state(void);
bool ble_hr_is_connected(void);
uint8_t ble_hr_get_bpm(void);
int8_t ble_hr_get_rssi(void);
const char *ble_hr_get_name(void);

#endif
```

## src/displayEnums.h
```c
/*
 * enums.h
 *
 * Created: 15.12.2022 11:47:44
 *  Author: Andre
 */ 


#ifndef ENUMS_H_
#define ENUMS_H_
//#define BIKE
//#define CICLOTTE
//#define SPRINTBOK
//#ifdef BIKE

enum String_Fields{
	NONE = 0,
	SF_VALUE0_LIGHT,
	SF_VALUE1_LIGHT,
	SF_VALUE2_LIGHT,
	SF_VALUE3_LIGHT,
	SF_VALUE4_LIGHT,
	SF_VALUE0_DARK,
	SF_VALUE1_DARK,
	SF_VALUE2_DARK,
	SF_VALUE3_DARK,
	SF_VALUE4_DARK,
	SF_LABEL0_LIGHT,
	SF_LABEL1_LIGHT,
	SF_LABEL2_LIGHT,
	SF_LABEL3_LIGHT,
	SF_LABEL4_LIGHT,
	SF_LABEL0_DARK,
	SF_LABEL1_DARK,
	SF_LABEL2_DARK,
	SF_LABEL3_DARK,
	SF_LABEL4_DARK,
	SF_LABEL10_LIGHT,
	SF_LABEL31_LIGHT,
	SF_LABEL10_DARK,
	SF_LABEL31_DARK,
	SF_LABEL40_DARK,
	SF_LABEL11_LIGHT,
	SF_LABEL11_DARK,
	SF_LABEL30_LIGHT,
	SF_LABEL30_DARK,
	SF_HALFTILE40_LINE1_LIGHT,
	SF_HALFTILE40_LINE2_LIGHT,
	SF_HALFTILE40_LINE3_LIGHT,
	SF_INFO_LINE0_LIGHT,
	SF_INFO_LINE1_LIGHT,
	SF_INFO_LINE2_LIGHT,
	SF_INFO_LINE3_LIGHT,
	SF_INFO_LINE4_LIGHT,
	SF_INFO_LINE0_DARK,
	SF_INFO_LINE1_DARK,
	SF_INFO_LINE2_DARK,
	SF_INFO_LINE3_DARK,
	SF_INFO_LINE4_DARK,
	SF_HALFTILE40_LINE1_DARK,
	SF_HALFTILE40_LINE2_DARK,
	SF_HALFTILE40_LINE3_DARK,
	SF_HALFTILE41_LABEL_LIGHT,
	SF_HALFTILE41_LABEL_DARK
	};

enum IMAGES {  ////////        BIKE IMAGES
	IMG_BG_DARK_HT40_NEUTRAL = 0,          // 0x00
	// PAGE 1
	
	IMG_BG_GRID_LIGHT,                      // 0x01
	IMG_TILE0_NOHRD_LOGO,                   // 0x02
	#ifdef LEGACY
	IMG_TILE0_BLANK_LIGHT,		              // 0x03
	#endif
	IMG_TILE1_BLANK_LIGHT = 0x04,           // 0x04
	IMG_TILE2_BLANK_LIGHT,                  // 0x05
	IMG_TILE3_BLANK_LIGHT,                  // 0x06
	IMG_TILE4_BLANK_LIGHT,                  // 0x07
	#ifdef LEGACY
	IMG_TILE0_BLANK_DARK,                   // 0x08
	#endif
	IMG_TILE1_BLANK_DARK = 0x09,            // 0x09
	IMG_TILE2_BLANK_DARK,                   // 0x0A
	IMG_TILE3_BLANK_DARK,                   // 0x0B
	IMG_TILE4_BLANK_DARK,                   // 0x0C
	#ifdef LEGACY
	IMG_TILE0_PRESSED_LIGHT,                // 0x0D
	#endif
	IMG_TILE1_PRESSED_LIGHT = 0x0E,         // 0x0E
	IMG_TILE2_PRESSED_LIGHT,                // 0x0F
	IMG_TILE3_PRESSED_LIGHT,                // 0x10
	IMG_TILE4_PRESSED_LIGHT,                // 0x11
	#ifdef LEGACY
	IMG_TILE0_PRESSED_DARK,                 // 0x12
	#endif
	IMG_TILE1_PRESSED_DARK = 0x13,          // 0x13
	IMG_TILE2_PRESSED_DARK,                 // 0x14
	IMG_TILE3_PRESSED_DARK,                 // 0x15
	IMG_TILE4_PRESSED_DARK,                 // 0x16
	IMG_HALFTILE10_BLANK_LIGHT,             // 0x17
	IMG_HALFTILE11_BLANK_LIGHT,             // 0x18
	IMG_HALFTILE30_BLANK_LIGHT,             // 0x19
	IMG_HALFTILE31_BLANK_LIGHT,             // 0x1A
	IMG_HALFTILE40_BLANK_LIGHT,             // 0x1B
	IMG_HALFTILE41_BLANK_LIGHT,             // 0x1C
	IMG_HALFTILE10_BLANK_DARK,              // 0x1D
	IMG_HALFTILE11_BLANK_DARK,              // 0x1E
	IMG_HALFTILE30_BLANK_DARK,              // 0x1F
	IMG_HALFTILE31_BLANK_DARK,              // 0x20
	IMG_HALFTILE40_BLANK_DARK,              // 0x21
	IMG_HALFTILE41_BLANK_DARK,              // 0x22
	IMG_HALFTILE40_BLANK_NEUTRAL,           // 0x23
	IMG_HALFTILE41_BLANK_NEUTRAL,           // 0x24
	IMG_HALFTILE10_PRESSED_LIGHT,           // 0x25
	IMG_HALFTILE11_PRESSED_LIGHT,           // 0x26
	IMG_HALFTILE20_PRESSED_LIGHT,           // 0x27
	IMG_HALFTILE21_PRESSED_LIGHT,           // 0x28
	IMG_HALFTILE30_PRESSED_LIGHT,           // 0x29
	IMG_HALFTILE31_PRESSED_LIGHT,           // 0x2A
	IMG_HALFTILE40_PRESSED_LIGHT,           // 0x2B
	IMG_HALFTILE41_PRESSED_LIGHT,           // 0x2C
	IMG_HALFTILE10_PRESSED_DARK,            // 0x2D
	IMG_HALFTILE11_PRESSED_DARK,            // 0x2E
	IMG_HALFTILE20_PRESSED_DARK,            // 0x2F
	IMG_HALFTILE21_PRESSED_DARK,            // 0x30
	IMG_HALFTILE30_PRESSED_DARK,            // 0x31
	IMG_HALFTILE31_PRESSED_DARK,            // 0x32
	IMG_HALFTILE40_PRESSED_DARK,            // 0x33
	IMG_HALFTILE41_PRESSED_DARK,            // 0x34
	#ifdef LEGACY
	IMG_TILE0_FRAME_LIGHT,                  // 0x35
	#endif
	IMG_TILE1_FRAME_LIGHT = 0x36,           // 0x36
	IMG_TILE2_FRAME_LIGHT,                  // 0x37
	IMG_TILE3_FRAME_LIGHT,                  // 0x38
	IMG_TILE4_FRAME_LIGHT,                  // 0x39
	IMG_HALFTILE10_FRAME_LIGHT,             // 0x3A
	IMG_HALFTILE11_FRAME_LIGHT,             // 0x3B
	IMG_HALFTILE20_FRAME_LIGHT,             // 0x3C
	IMG_HALFTILE21_FRAME_LIGHT,             // 0x3D
	IMG_HALFTILE30_FRAME_LIGHT,             // 0x3E
	IMG_HALFTILE31_FRAME_LIGHT,             // 0x3F
	IMG_HALFTILE40_FRAME_LIGHT,             // 0x40
	IMG_HALFTILE41_FRAME_LIGHT,             // 0x41
	#ifdef LEGACY
	IMG_TILE0_FRAME_DARK,                   // 0x42
	#endif
	IMG_TILE1_FRAME_DARK = 0x43,            // 0x43
	IMG_TILE2_FRAME_DARK,                   // 0x44
	IMG_TILE3_FRAME_DARK,                   // 0x45
	IMG_TILE4_FRAME_DARK,                   // 0x46
	IMG_HALFTILE10_FRAME_DARK,              // 0x47
	IMG_HALFTILE11_FRAME_DARK,              // 0x48
	IMG_HALFTILE20_FRAME_DARK,              // 0x49
	IMG_HALFTILE21_FRAME_DARK,              // 0x4A
	IMG_HALFTILE30_FRAME_DARK,              // 0x4B
	IMG_HALFTILE31_FRAME_DARK,              // 0x4C
	IMG_HALFTILE40_FRAME_DARK,              // 0x4D
	IMG_HALFTILE41_FRAME_DARK,              // 0x4E
	IMG_RINGTILE10_FRAME_LIGHT,             // 0x4F
	IMG_RINGTILE11_FRAME_LIGHT,             // 0x50
	IMG_RINGTILE20_FRAME_LIGHT,             // 0x51
	IMG_RINGTILE21_FRAME_LIGHT,             // 0x52
	IMG_RINGTILE30_FRAME_LIGHT,             // 0x53
	IMG_RINGTILE31_FRAME_LIGHT,             // 0x54
	IMG_TILE1_FRAME2_LIGHT,                 // 0x55
	IMG_TILE2_FRAME2_LIGHT,                 // 0x56
	IMG_TILE3_FRAME2_LIGHT,                 // 0x57
	IMG_TILE1_FRAME2_DARK,                  // 0x58
	IMG_TILE2_FRAME2_DARK,                  // 0x59
	IMG_TILE3_FRAME2_DARK,                  // 0x5A
	IMG_RINGTILE10_FRAME_DARK,              // 0x5B
	IMG_RINGTILE11_FRAME_DARK,              // 0x5C
	IMG_RINGTILE20_FRAME_DARK,              // 0x5D
	IMG_RINGTILE21_FRAME_DARK,              // 0x5E
	IMG_RINGTILE30_FRAME_DARK,              // 0x5F
	IMG_RINGTILE31_FRAME_DARK,              // 0x60
	// PAGE 2
	IMG_BG_GRID_LIGHT_TILE4_DARK,           // 0x61
#ifdef LEGACY	//IMG_TILE0_CHECK,                        // 0x62
	//IMG_TILE0_FREE,                         // 0x63
#endif
	IMG_TILE0_DISTANCE = 0x64,              // 0x64
	IMG_TILE0_FINISH,                       // 0x65
#ifdef LEGACY	//IMG_TILE0_STOP,                         // 0x66
#endif
	IMG_TILE0_TIME = 0x67,                  // 0x67
	IMG_TILE1_TIME_ICON_LIGHT,              // 0x68
	IMG_TILE2_DISTANCE_ICON_LIGHT,          // 0x69
	IMG_TILE3_FREE_ICON_LIGHT,              // 0x6A
	IMG_TILE4_SETTINGS_ICON_LIGHT,          // 0x6B
	IMG_TILE1_TIME_ICON_DARK,               // 0x6C
	IMG_TILE2_DISTANCE_ICON_DARK,           // 0x6D
	IMG_TILE3_FREE_ICON_DARK,               // 0x6E
	IMG_TILE4_SETTINGS_ICON_DARK,           // 0x6F
	IMG_TILE1_CHECK_ICON_LIGHT,             // 0x70
	IMG_TILE2_CANCEL_ICON_LIGHT,            // 0x71
	IMG_TILE1_CHECK_ICON_DARK,              // 0x72
	IMG_TILE2_CANCEL_ICON_DARK,             // 0x73
	IMG_HALFTILE41_LEFT_ARROW_ICON_LIGHT,   // 0x74
	IMG_HALFTILE41_LEFT_ARROW_ICON_DARK,    // 0x75
	IMG_HALFTILE41_STOP_ICON_LIGHT,         // 0x76
	IMG_HALFTILE41_STOP_ICON_DARK,          // 0x77
	IMG_HALFTILE40_PAUSE_ICON_LIGHT,        // 0x78
	IMG_HALFTILE40_PAUSE_ICON_DARK,         // 0x79
	
	IMG_HALFTILE40_PLUS_ICON_LIGHT,         // 0x7A
	IMG_HALFTILE41_MINUS_ICON_LIGHT,        // 0x7B
	IMG_HALFTILE40_PLUS_ICON_DARK,          // 0x7C
	IMG_HALFTILE41_MINUS_ICON_DARK,         // 0x7D
	IMG_HALFTILE40_PLAY_ICON_LIGHT,         // 0x7E
	IMG_HALFTILE40_PLAY_ICON_DARK,          // 0x7F
	IMG_TILE2_SUN_ICON_LIGHT,               // 0x80
	IMG_TILE2_MOON_ICON_DARK,               // 0x81
	IMG_TILE3_HR_ICON_LIGHT,                // 0x82
	IMG_TILE3_HR_ICON_DARK,                 // 0x83
	IMG_TILE1_ENGLISH_ICON,                 // 0x84
	IMG_TILE1_GERMAN_ICON,                  // 0x85
	IMG_TILE1_FRENCH_ICON,                  // 0x86
	IMG_TILE1_SPANISH_ICON,                 // 0x87
	IMG_TILE1_US_ICON,                      // 0x88
	IMG_TILE0_SETTINGS,                     // 0x89
	IMG_TILE4_HOME_LIGHT,                   // 0x8A
	IMG_TILE4_HOME_DARK,                    // 0x8B
	IMG_TILE4_NEXT_ICON_LIGHT,              // 0x8C
	IMG_TILE4_NEXT_ICON_DARK,               // 0x8D
	IMG_TILE3_BT_ICON_OFF_LIGHT,            // 0x8E
	IMG_TILE3_BT_ICON_OFF_DARK,             // 0x8F
	IMG_TILE3_BT_ICON_ON,                   // 0x90
	IMG_TILE2_CALIBRATE_DOWN_LIGHT,         // 0x91
	IMG_TILE2_CALIBRATE_DOWN_DARK,          // 0x92
	IMG_TILE2_CALIBRATE_UP_LIGHT,           // 0x93
	IMG_TILE2_CALIBRATE_UP_DARK,            // 0x94
	IMG_TILE1_INFO_LIGHT,                   // 0x95
	IMG_TILE1_INFO_DARK,                    // 0x96
	IMG_HALFTILE41_HOME_ICON_LIGHT,         // 0x97
	IMG_HALFTILE41_HOME_ICON_DARK,          // 0x98
	IMG_TILE0_INFO_ICON,                    // 0x99
	#ifdef LEGACY
	IMG_TILE0_BLANK_NEUTRAL,                // 0x9A
	#endif
	IMG_HALFTILE40_REFRESH_HR = 0x9B,       // 0x9B
	IMG_HALFTILE40_WAIT_HR_1_3,             // 0x9C
	IMG_HALFTILE40_WAIT_HR_2_3,             // 0x9D
	IMG_HALFTILE40_WAIT_HR_3_3,             // 0x9E
	IMG_HALFTILE41_PAUSED_ICON_DARK,        // 0x9F
	IMG_HALFTILE41_PAUSED_ICON_LIGHT,       // 0xA0
	IMG_TILE4_CHECK_ICON_DARK,              // 0xA1
	IMG_TILE4_CHECK_ICON_LIGHT,             // 0xA2
	// PAGE 3
	IMG_BG_GRID_DARK,                       // 0xA3
	IMG_TILE1_RING_1_9,                     // 0xA4
	IMG_TILE1_RING_2_9,                     // 0xA5
	IMG_TILE1_RING_3_9,                     // 0xA6
	IMG_TILE1_RING_4_9,                     // 0xA7
	IMG_TILE1_RING_5_9,                     // 0xA8
	IMG_TILE1_RING_6_9,                     // 0xA9
	IMG_TILE1_RING_7_9,                     // 0xAA
	IMG_TILE1_RING_8_9,                     // 0xAB
	IMG_TILE1_RING_9_9,                     // 0xAC
	IMG_TILE2_RING_1_9,                     // 0xAD
	IMG_TILE2_RING_2_9,                     // 0xAE
	IMG_TILE2_RING_3_9,                     // 0xAF
	IMG_TILE2_RING_4_9,                     // 0xB0
	IMG_TILE2_RING_5_9,                     // 0xB1
	IMG_TILE2_RING_6_9,                     // 0xB2
	IMG_TILE2_RING_7_9,                     // 0xB3
	IMG_TILE2_RING_8_9,                     // 0xB4
	IMG_TILE2_RING_9_9,                     // 0xB5
	IMG_TILE3_RING_1_9,                     // 0xB6
	IMG_TILE3_RING_2_9,                     // 0xB7
	IMG_TILE3_RING_3_9,                     // 0xB8
	IMG_TILE3_RING_4_9,                     // 0xB9
	IMG_TILE3_RING_5_9,                     // 0xBA
	IMG_TILE3_RING_6_9,                     // 0xBB
	IMG_TILE3_RING_7_9,                     // 0xBC
	IMG_TILE3_RING_8_9,                     // 0xBD
	IMG_TILE3_RING_9_9,                     // 0xBE
	IMG_HR_INDICATOR_ICON_OFF,              // 0xBF
	IMG_HR_INDICATOR_ICON_ON,               // 0xC0
	// PAGE 4
	IMG_BG_GRID_DARK_TILE4_DARK,            // 0xC1
	// PAGE 5
	IMG_BG_LIGHT,                           // 0xC2
	// PAGE 6
	IMG_BG_DARK,                            // 0xC3
	// PAGE 7
	IMG_BG_BOOT,                            // 0xC4
	// PAGE 8
	IMG_BG_HALFGRID_LIGHT,                  // 0xC5
	IMG_TILE3_QRCODE,                       // 0xC6
	IMG_TILE1_NOHRD_INFO,                   // 0xC7
	IMG_HALFTILE41_DISCONBT_LIGHT,          // 0xC8
	IMG_HALFTILE41_DISCONBT_DARK,           // 0xC9
	IMG_TILE3_CONTRAST_ICON_LIGHT,          // 0xCA
	IMG_TILE3_CONTRAST_ICON_DARK,           // 0xCB
	IMG_HALFTILE40_VERSION_NUMBER,          // 0xCC
	// PAGE 9
	IMG_BG_HALFGRID_DARK,                   // 0xCD
	// PAGE 10
	IMG_BG_SS_1,                            // 0xCE
	// PAGE 11
	IMG_BG_SS_2,                            // 0xCF
	// PAGE 12
	IMG_BG_SS_3,                            // 0xD0
	// PAGE 13
	IMG_BG_SS_4,                            // 0xD1
	// PAGE 14
	IMG_BG_LIGHT_HT40_NEUTRAL,              // 0xD2
	// PAGE 15
	IMG_BG_CALIBRATION,                     // 0xD3
	// PAGE 16
	IMG_BG_BLACK,                           // 0xD4
	IMG_TILE2_CUSTOMIZE_ICON_LIGHT,			// 0xD5
	IMG_TILE1_CUSTOMIZE_ICON_DARK,			// 0xD6
	IMG_TILE3_SETUP_ICON_LIGHT,				// 0xD7
	IMG_TILE2_SETUP_ICON_DARK,				// 0xD8
	IMG_TILE1_FULL_BRIGHTNESS_ICON_LIGHT,	// 0xD9
	IMG_TILE1_FULL_BRIGHTNESS_ICON_DARK,	// 0xDA
	IMG_TILE2_HALF_BRIGHTNESS_ICON_LIGHT,	// 0xDB
	IMG_TILE2_HALF_BRIGHTNESS_ICON_DARK,	// 0xDC
	IMG_TILE3_LOW_BRIGHTNESS_ICON_LIGHT,	// 0xDD
	IMG_TILE3_LOW_BRIGHTNESS_ICON_DARK,		// 0xDE
	IMG_TILE1_BATTERY_ICON_LIGHT,			// 0xDF
	IMG_TILE1_BATTERY_ICON_DARK,			// 0xE0
	IMG_TILE1_GRID_ICON_LIGHT,				// 0xE1
	IMG_TILE1_GRID_ICON_DARK,				// 0xE2
	IMG_TILE0_CUSTOM_LOGO,
	IMG_TILE0_SETUP_LOGO,
	IMG_TILE0_CONTRAST_LOGO,
	IMG_TILE4_BACK_ICON_LIGHT,
	IMG_TILE4_BACK_ICON_DARK,
};

enum GIFS {
	GIF_CALIBRATE_UP,
	GIF_CALIBRATE_DOWN
};

enum A_CMDS {
	A_NONE=0,
	MAIN_MENU_LIGHT_MODE,
	MAIN_MENU_DARK_MODE
};

typedef enum {
    BTN_NONE = 0,   // 0
    BTN_TILE0,      // 1
    BTN_TILE1,      // 2
    BTN_TILE2,      // 3
    BTN_TILE3,      // 4
    BTN_TILE4,      // 5
    BTN_TILE1T,     // 6
    BTN_TILE1B,     // 7
    BTN_TILE2T,     // 8
    BTN_TILE2B,     // 9
    BTN_TILE3T,     // 10
    BTN_TILE3B,     // 11
    BTN_TILE4T,     // 12
    BTN_TILE4B,     // 13
    BTN_TILE1L,     // 14
    BTN_TILE1R,     // 15
    BTN_TILE2L,     // 16
    BTN_TILE2R,     // 17
    BTN_TILE3L,     // 18
    BTN_TILE3R,     // 19
    BTN_WAKEUP      // 20
} ButtonState;

enum BUTTONS_ACTION_IDS{
BTN_ACTION_NONE = 0, // 0
BTN_ACTION_HIDDEN_BUTTON, // 1
BTN_ACTION_GOTO_MAIN_MENU, // 2
BTN_ACTION_GOTO_TIME_SELECTION, // 3
BTN_ACTION_GOTO_CUSTOM_TIME_SELECTION, // 4
BTN_ACTION_GOTO_CUSTOM_DISTANCE_SELECTION, // 5
BTN_ACTION_GOTO_DISTANCE_SELECTION, // 6
BTN_ACTION_GOTO_FREE_SESSION, // 7
BTN_ACTION_GOTO_CONNECT, // 8
BTN_ACTION_INCREASE_TIME, // 9
BTN_ACTION_DECREASE_TIME, // 10
BTN_ACTION_BIG_INCREASE_TIME, // 11
BTN_ACTION_BIG_DECREASE_TIME, // 12
BTN_ACTION_INCREASE_DISTANCE, // 13
BTN_ACTION_DECREASE_DISTANCE, // 14
BTN_ACTION_BIG_INCREASE_DISTANCE, // 15
BTN_ACTION_BIG_DECREASE_DISTANCE, // 16
BTN_ACTION_TILE0, // 17
BTN_ACTION_TILE1, // 18
BTN_ACTION_TILE2, // 19
BTN_ACTION_TILE3, // 20
BTN_ACTION_TILE4, // 21
BTN_ACTION_START_TIME_SESSION, // 22
BTN_ACTION_START_DISTANCE_SESSION, // 23
BTN_ACTION_CYCLE_SESSION_TILE1, // 24
BTN_ACTION_CYCLE_SESSION_TILE2, // 25
BTN_ACTION_CYCLE_SESSION_TILE3, // 26
BTN_ACTION_STOP_TIME_SESSION, // 27
BTN_ACTION_LEFTCYCLE_SESSION_TILE1, // 28
BTN_ACTION_RIGHTCYCLE_SESSION_TILE1, // 29
BTN_ACTION_LEFTCYCLE_SESSION_TILE2, // 30
BTN_ACTION_RIGHTCYCLE_SESSION_TILE2, // 31
BTN_ACTION_LEFTCYCLE_SESSION_TILE3, // 32
BTN_ACTION_RIGHTCYCLE_SESSION_TILE3, // 33
BTN_ACTION_TOGGLE_LANGUAGE, // 34
BTN_ACTION_TOGGLE_LDMODE, // 35
BTN_ACTION_GOTO_HRCONNECT, // 36
BTN_ACTION_GOTO_SETTINGS, // 37
BTN_ACTION_GOTO_SETTINGS2, // 38
BTN_ACTION_GOTO_INFO, // 39
BTN_ACTION_GOTO_CALIBRATE_UP, // 40
BTN_ACTION_GOTO_CALIBRATE_DOWN, // 41
BTN_ACTION_GOTO_CALIBRATE_END, // 42
BTN_ACTION_TOGGLE_BLUETOOTH, // 43
BTN_ACTION_UNLOCK_DEV_MODE, // 44
BTN_ACTION_RETURN_FROM_INFO, // 45
BTN_ACTION_STOP_SESSION, // 46
BTN_ACTION_PAUSE_SESSION, // 47
BTN_ACTION_RESUME_SESSION, // 48
BTN_ACTION_WAKEUP, // 49
BTN_ACTION_REFRESH_HR, // 50
BTN_ACTION_QUIT_PEER_CONNECTION, // 51
BTN_ACTION_CONFIRM_CONFIRM, // 52
BTN_ACTION_CONFIRM_CANCEL, // 53
BTN_ACTION_GOTO_CONTRAST, // 54
BTN_ACTION_CONTRAST_HIGH, // 55
BTN_ACTION_CONTRAST_MID, // 56
BTN_ACTION_CONTRAST_LOW, // 57
BTN_ACTION_RETURN_FROM_CALIBRATE, // 58
BTN_ACTION_BRIGHTNESS, // 59
BTN_ACTION_INCREASE_ANGLE, // 60
BTN_ACTION_DECREASE_ANGLE, // 61
BTN_ACTION_CUSTOMIZE_SETTINGS,
BTN_ACTION_SETUP_SETTINGS,
BTN_ACTION_TOGGLE_POWER_SOURCE,
BTN_ACTION_GOTO_INCLINE_CORRECTION_SCREEN,
BTN_ACTION_INCREASE_INCLINE_CORRECTION,
BTN_ACTION_DECREASE_INCLINE_CORRECTION,
BTN_ACTION_CYCLE_CHANNEL_MODES
};

enum COMMANDIDS{
	CMD_BUTTON = 0xa2,
	CMD_SWIPE = 0xc9,
	CMD_ASCII = 0x9f
};
enum RESPONSEIDS{
	BTN_PRESS = 0x31,
	BTN_RELEASE = 0x30,
	SWIPE_UP = 0x00,
	SWIPE_DOWN = 0x01,
	SWIPE_LEFT = 0x02,
	SWIPE_RIGHT = 0x03
};



#endif /* ENUMS_H_ */
```
